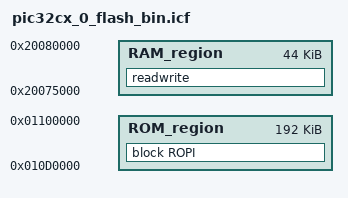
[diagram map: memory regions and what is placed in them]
/*###ICF### Section handled by ICF editor, don't touch! ****/
/*-Editor annotation file-*/
/* IcfEditorFile="$TOOLKIT_DIR$\config\ide\IcfEditor\cortex_v1_0.xml" */
/*-Specials-*/
define symbol __DONT_CARE__        = 0x00000000;
/*-Prime Stack Reserved Memory Resources (136K ROM, 44K RAM)-*/
define symbol __prime_RAM_size__   = 0x0000B000;
define symbol __prime_ROM_size__   = 0x00030000; /* This is to make the ROM start at 0x010D0000 */
/*-Memory Regions-*/
define symbol __region_RAM_start__ = 0x20000000;
define symbol __region_RAM_end__   = 0x20080000;
define symbol __region_ROM_start__ = 0x01000000;
define symbol __region_ROM_end__   = 0x01200000;
define symbol __bank_ROM_size__    = 0x00100000; /* This is to use only the first memory bank */
/*-PRIME Memory Regions-*/
define symbol __prime_RAM_start__  = __region_RAM_end__ - __prime_RAM_size__;
define symbol __prime_RAM_end__    = __region_RAM_end__;
define symbol __prime_ROM_start__  = __region_ROM_end__ - __prime_ROM_size__ - __bank_ROM_size__;
define symbol __prime_ROM_end__    = __region_ROM_end__ - __bank_ROM_size__;
/*-Sizes-*/
if (!isdefinedsymbol(__size_cstack__)) {
define symbol __size_cstack__      = __DONT_CARE__;
}
if (!isdefinedsymbol(__size_heap__)) {
define symbol __size_heap__        = __DONT_CARE__;
}
/**** End of ICF editor section. ###ICF###*/

define memory mem with size = 4G;
define region RAM_region    = mem:[from __prime_RAM_start__ to __prime_RAM_end__];
define region ROM_region    = mem:[from __prime_ROM_start__ to __prime_ROM_end__];

initialize by copy { readwrite };

initialize manually { section .data };

do not initialize { section .noinit, 
		    section .bss
};

define movable block ROPI with alignment = 4, fixed order
{
   ro object prime_header.o,
   ro ,
   ro data,
};

place in ROM_region { block ROPI};
place in RAM_region { readwrite };
